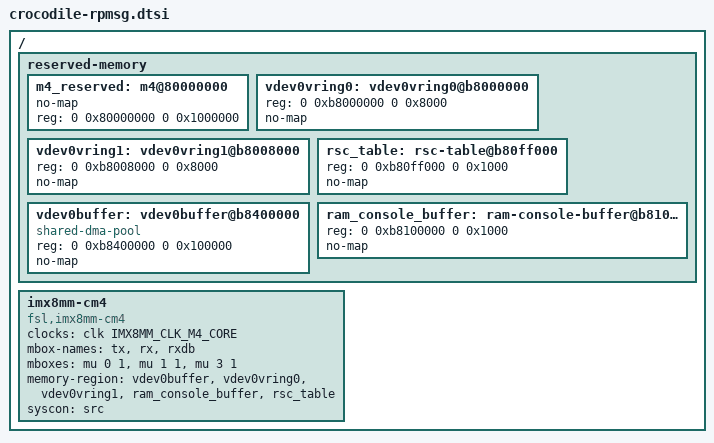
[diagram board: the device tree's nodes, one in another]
// SPDX-License-Identifier: (GPL-2.0+ OR MIT)
/*
 * Copyright 2020 NXP
 * Copyright (C) 2021 Leica Geosystems AG
 */

/ {
	reserved-memory {
		#address-cells = <2>;
		#size-cells = <2>;
		ranges;

		m4_reserved: m4@80000000 {
			no-map;
			reg = <0 0x80000000 0 0x1000000>;
		};

		vdev0vring0: vdev0vring0@b8000000 {
			reg = <0 0xb8000000 0 0x8000>;
			no-map;
		};

		vdev0vring1: vdev0vring1@b8008000 {
			reg = <0 0xb8008000 0 0x8000>;
			no-map;
		};

		rsc_table: rsc-table@b80ff000 {
			reg = <0 0xb80ff000 0 0x1000>;
			no-map;
		};

		vdev0buffer: vdev0buffer@b8400000 {
			compatible = "shared-dma-pool";
			reg = <0 0xb8400000 0 0x100000>;
			no-map;
		};

		ram_console_buffer: ram-console-buffer@b8100000 {
			reg = <0 0xb8100000 0 0x1000>;
			no-map;
		};
	};

	imx8mm-cm4 {
		compatible = "fsl,imx8mm-cm4";
		clocks = <&clk IMX8MM_CLK_M4_CORE>;
		mbox-names = "tx", "rx", "rxdb";
		mboxes = <&mu 0 1
			  &mu 1 1
			  &mu 3 1>;
		memory-region = <&vdev0buffer>, <&vdev0vring0>, <&vdev0vring1>,
				<&ram_console_buffer>, <&rsc_table>;
		syscon = <&src>;
	};
};
